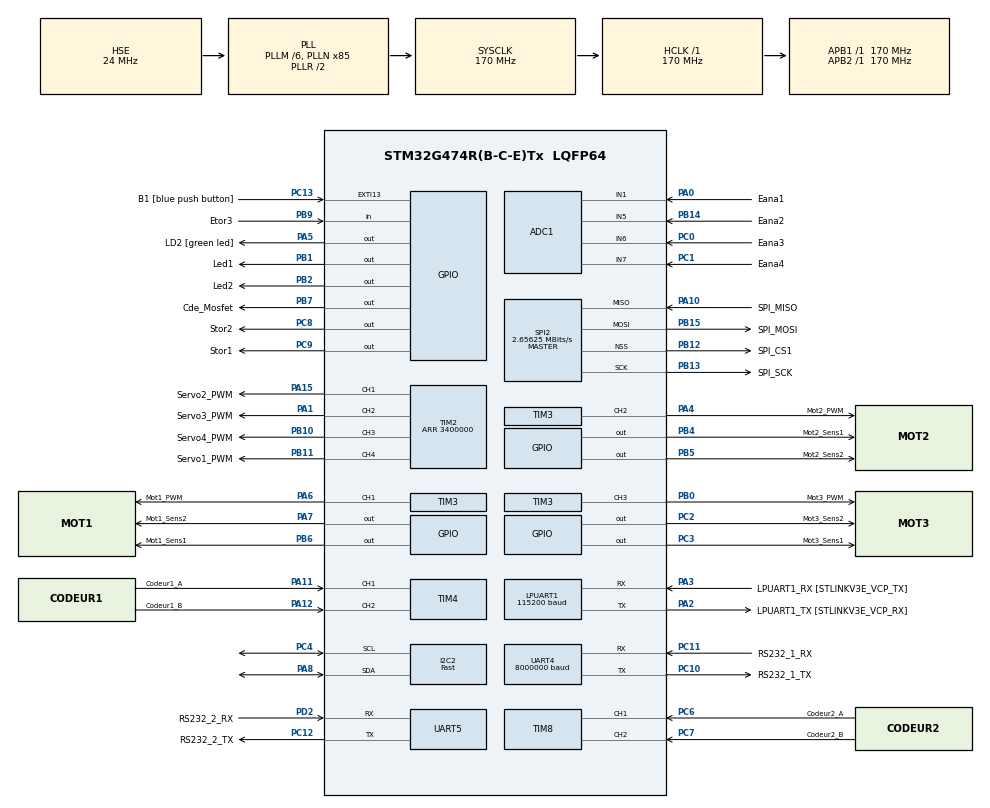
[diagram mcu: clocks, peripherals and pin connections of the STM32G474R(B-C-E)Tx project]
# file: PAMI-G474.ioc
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ADC1.Channel-0\#ChannelRegularConversion=ADC_CHANNEL_1
ADC1.NbrOfConversionFlag=1
ADC1.OffsetNumber-0\#ChannelRegularConversion=ADC_OFFSET_NONE
ADC1.Rank-0\#ChannelRegularConversion=1
ADC1.SamplingTime-0\#ChannelRegularConversion=ADC_SAMPLETIME_2CYCLES_5
ADC1.master=1
Dma.Request0=UART4_TX
Dma.UART4_TX.0.Direction=DMA_MEMORY_TO_PERIPH
Dma.UART4_TX.0.EventEnable=DISABLE
Dma.UART4_TX.0.Instance=DMA1_Channel1
Dma.UART4_TX.0.MemDataAlignment=DMA_MDATAALIGN_BYTE
Dma.UART4_TX.0.MemInc=DMA_MINC_ENABLE
Dma.UART4_TX.0.Mode=DMA_NORMAL
Dma.UART4_TX.0.PeriphDataAlignment=DMA_PDATAALIGN_BYTE
Dma.UART4_TX.0.PeriphInc=DMA_PINC_DISABLE
Dma.UART4_TX.0.Polarity=HAL_DMAMUX_REQ_GEN_RISING
Dma.UART4_TX.0.Priority=DMA_PRIORITY_LOW
Dma.UART4_TX.0.RequestNumber=1
Dma.UART4_TX.0.SignalID=NONE
Dma.UART4_TX.0.SyncEnable=DISABLE
Dma.UART4_TX.0.SyncPolarity=HAL_DMAMUX_SYNC_NO_EVENT
Dma.UART4_TX.0.SyncRequestNumber=1
Dma.UART4_TX.0.SyncSignalID=NONE
I2C2.I2C_Speed_Mode=I2C_Fast
I2C2.Timing=0x40621236
LPUART1.BaudRate=115200
Mcu.Family=STM32G4
Mcu.Name=STM32G474R(B-C-E)Tx
Mcu.Package=LQFP64
NVIC.DMA1_Channel1_IRQn=true\:0\:0\:false\:false\:true\:false\:true\:true
NVIC.EXTI15_10_IRQn=true\:0\:0\:false\:false\:true\:true\:true\:true
NVIC.LPUART1_IRQn=true\:0\:0\:false\:false\:true\:true\:true\:true
NVIC.PriorityGroup=NVIC_PRIORITYGROUP_4
NVIC.UART4_IRQn=true\:0\:0\:false\:false\:true\:true\:true\:true
PA0.GPIO_Label=Eana1
PA0.Mode=IN1-Single-Ended
PA0.Signal=ADC1_IN1
PA1.GPIO_Label=Servo3_PWM
PA1.Signal=S_TIM2_CH2
PA10.GPIO_Label=SPI_MISO
PA10.Mode=Full_Duplex_Master
PA10.Signal=SPI2_MISO
PA11.GPIO_Label=Codeur1_A
PA11.Signal=S_TIM4_CH1
PA12.GPIO_Label=Codeur1_B
PA12.Signal=S_TIM4_CH2
PA13.GPIO_Label=T_SWDIO
PA13.Signal=SYS_JTMS-SWDIO
PA14.GPIO_Label=T_SWCLK
PA14.Signal=SYS_JTCK-SWCLK
PA15.GPIO_Label=Servo2_PWM
PA15.Signal=S_TIM2_CH1
PA2.GPIO_Label=LPUART1_TX [STLINKV3E_VCP_RX]
PA2.Mode=Asynchronous
PA2.Signal=LPUART1_TX
PA3.GPIO_Label=LPUART1_RX [STLINKV3E_VCP_TX]
PA3.Mode=Asynchronous
PA3.Signal=LPUART1_RX
PA4.GPIO_Label=Mot2_PWM
PA4.Signal=S_TIM3_CH2
PA5.GPIO_Label=LD2 [green led]
PA5.Signal=GPIO_Output
PA6.GPIO_Label=Mot1_PWM
PA6.Signal=S_TIM3_CH1
PA7.GPIO_Label=Mot1_Sens2
PA7.Signal=GPIO_Output
PA8.Mode=I2C
PA8.Signal=I2C2_SDA
PB0.GPIO_Label=Mot3_PWM
PB0.Signal=S_TIM3_CH3
PB1.GPIO_Label=Led1
PB1.Signal=GPIO_Output
PB10.GPIO_Label=Servo4_PWM
PB10.Signal=S_TIM2_CH3
PB11.GPIO_Label=Servo1_PWM
PB11.Signal=S_TIM2_CH4
PB12.GPIO_Label=SPI_CS1
PB12.Mode=NSS_Signal_Hard_Output
PB12.Signal=SPI2_NSS
PB13.GPIO_Label=SPI_SCK
PB13.Mode=Full_Duplex_Master
PB13.Signal=SPI2_SCK
PB14.GPIO_Label=Eana2
PB14.Mode=IN5-Single-Ended
PB14.Signal=ADC1_IN5
PB15.GPIO_Label=SPI_MOSI
PB15.Mode=Full_Duplex_Master
PB15.Signal=SPI2_MOSI
PB2.GPIO_Label=Led2
PB2.Signal=GPIO_Output
PB3.GPIO_Label=T_SWO
PB3.Signal=SYS_JTDO-SWO
PB4.GPIO_Label=Mot2_Sens1
PB4.Signal=GPIO_Output
PB5.GPIO_Label=Mot2_Sens2
PB5.Signal=GPIO_Output
PB6.GPIO_Label=Mot1_Sens1
PB6.Signal=GPIO_Output
PB7.GPIO_Label=Cde_Mosfet
PB7.Signal=GPIO_Output
PB9.GPIO_Label=Etor3
PB9.GPIO_PuPd=GPIO_PULLUP
PB9.Signal=GPIO_Input
PC0.GPIO_Label=Eana3
PC0.Mode=IN6-Single-Ended
PC0.Signal=ADC1_IN6
PC1.GPIO_Label=Eana4
PC1.Mode=IN7-Single-Ended
PC1.Signal=ADC1_IN7
PC10.GPIO_Label=RS232_1_TX
PC10.Mode=Asynchronous
PC10.Signal=UART4_TX
PC11.GPIO_Label=RS232_1_RX
PC11.Mode=Asynchronous
PC11.Signal=UART4_RX
PC12.GPIO_Label=RS232_2_TX
PC12.Mode=Asynchronous
PC12.Signal=UART5_TX
PC13.GPIO_Label=B1 [blue push button]
PC13.Signal=GPXTI13
PC14-OSC32_IN.GPIO_Label=RCC_OSC32_IN
PC14-OSC32_IN.Signal=RCC_OSC32_IN
PC15-OSC32_OUT.GPIO_Label=RCC_OSC32_OUT
PC15-OSC32_OUT.Signal=RCC_OSC32_OUT
PC2.GPIO_Label=Mot3_Sens2
PC2.Signal=GPIO_Output
PC3.GPIO_Label=Mot3_Sens1
PC3.Signal=GPIO_Output
PC4.Mode=I2C
PC4.Signal=I2C2_SCL
PC6.GPIO_Label=Codeur2_A
PC6.Signal=S_TIM8_CH1
PC7.GPIO_Label=Codeur2_B
PC7.Signal=S_TIM8_CH2
PC8.GPIO_Label=Stor2
PC8.Signal=GPIO_Output
PC9.GPIO_Label=Stor1
PC9.Signal=GPIO_Output
PD2.GPIO_Label=RS232_2_RX
PD2.Mode=Asynchronous
PD2.Signal=UART5_RX
PF0-OSC_IN.GPIO_Label=RCC_OSC_IN
PF0-OSC_IN.Mode=HSE-External-Oscillator
PF0-OSC_IN.Signal=RCC_OSC_IN
PF1-OSC_OUT.GPIO_Label=RCC_OSC_OUT
PF1-OSC_OUT.Mode=HSE-External-Oscillator
PF1-OSC_OUT.Signal=RCC_OSC_OUT
ProjectManager.HeapSize=0x200
ProjectManager.StackSize=0x400
ProjectManager.TargetToolchain=STM32CubeIDE
RCC.ADC12Freq_Value=170000000
RCC.ADC345Freq_Value=170000000
RCC.AHBFreq_Value=170000000
RCC.APB1Freq_Value=170000000
RCC.APB1TimFreq_Value=170000000
RCC.APB2Freq_Value=170000000
RCC.APB2TimFreq_Value=170000000
RCC.CortexFreq_Value=170000000
RCC.EXTERNAL_CLOCK_VALUE=12288000
RCC.HCLKFreq_Value=170000000
RCC.HSE_VALUE=24000000
RCC.HSI48_VALUE=48000000
RCC.HSI_VALUE=16000000
RCC.LSE_VALUE=32768
RCC.PLLM=RCC_PLLM_DIV6
RCC.PLLN=85
RCC.PLLSourceVirtual=RCC_PLLSOURCE_HSE
RCC.RTCClockSelection=RCC_RTCCLKSOURCE_LSE
RCC.SYSCLKFreq_VALUE=170000000
RCC.SYSCLKSource=RCC_SYSCLKSOURCE_PLLCLK
RCC.USBFreq_Value=170000000
RCC.VCOOutputFreq_Value=340000000
SH.S_TIM2_CH1.0=TIM2_CH1,PWM Generation1 CH1
SH.S_TIM2_CH2.0=TIM2_CH2,PWM Generation2 CH2
SH.S_TIM2_CH3.0=TIM2_CH3,PWM Generation3 CH3
SH.S_TIM2_CH4.0=TIM2_CH4,PWM Generation4 CH4
SH.S_TIM3_CH1.0=TIM3_CH1,PWM Generation1 CH1
SH.S_TIM3_CH2.0=TIM3_CH2,PWM Generation2 CH2
SH.S_TIM3_CH3.0=TIM3_CH3,PWM Generation3 CH3
SH.S_TIM4_CH1.0=TIM4_CH1,Encoder_Interface
SH.S_TIM4_CH2.0=TIM4_CH2,Encoder_Interface
SH.S_TIM8_CH1.0=TIM8_CH1,Encoder_Interface
SH.S_TIM8_CH2.0=TIM8_CH2,Encoder_Interface
SPI2.BaudRatePrescaler=SPI_BAUDRATEPRESCALER_64
SPI2.CalculateBaudRate=2.65625 MBits/s
SPI2.DataSize=SPI_DATASIZE_8BIT
SPI2.Direction=SPI_DIRECTION_2LINES
SPI2.Mode=SPI_MODE_MASTER
SPI2.VirtualNSS=VM_NSSHARD
SPI2.VirtualType=VM_MASTER
TIM2.Channel-PWM\ Generation1\ CH1=TIM_CHANNEL_1
TIM2.Channel-PWM\ Generation2\ CH2=TIM_CHANNEL_2
TIM2.Channel-PWM\ Generation3\ CH3=TIM_CHANNEL_3
TIM2.Channel-PWM\ Generation4\ CH4=TIM_CHANNEL_4
TIM2.PeriodNoDither=3400000
TIM3.Channel-PWM\ Generation1\ CH1=TIM_CHANNEL_1
TIM3.Channel-PWM\ Generation2\ CH2=TIM_CHANNEL_2
TIM3.Channel-PWM\ Generation3\ CH3=TIM_CHANNEL_3
TIM3.PeriodNoDither=8500
TIM3.PulseNoDither_3=800
TIM4.EncoderMode=TIM_ENCODERMODE_TI12
TIM8.EncoderMode=TIM_ENCODERMODE_TI12
UART4.BaudRate=8000000
UART4.Mode=MODE_TX
UART4.TxPinLevelInvertParam=UART_ADVFEATURE_TXINV_ENABLE
VP_SYS_VS_DBSignals.Mode=DisableDeadBatterySignals
board=NUCLEO-G474RE

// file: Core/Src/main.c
/* USER CODE BEGIN Header */
/**
  ******************************************************************************
  * @file           : main.c
  * @brief          : Main program body
  ******************************************************************************
  * @attention
  *
  * Copyright (c) 2026 STMicroelectronics.
  * All rights reserved.
  *
  * This software is licensed under terms that can be found in the LICENSE file
  * in the root directory of this software component.
  * If no LICENSE file comes with this software, it is provided AS-IS.
  *
  ******************************************************************************
  */
/* USER CODE END Header */
#include "main.h"

ADC_HandleTypeDef hadc1;

I2C_HandleTypeDef hi2c2;

UART_HandleTypeDef hlpuart1;
UART_HandleTypeDef huart4;
UART_HandleTypeDef huart5;
DMA_HandleTypeDef hdma_uart4_tx;

SPI_HandleTypeDef hspi2;

TIM_HandleTypeDef htim2;
TIM_HandleTypeDef htim3;
TIM_HandleTypeDef htim4;
TIM_HandleTypeDef htim8;

void SystemClock_Config(void);
static void MX_GPIO_Init(void);
static void MX_DMA_Init(void);
static void MX_UART4_Init(void);
static void MX_UART5_Init(void);
static void MX_I2C2_Init(void);
static void MX_SPI2_Init(void);
static void MX_TIM2_Init(void);
static void MX_TIM3_Init(void);
static void MX_TIM4_Init(void);
static void MX_TIM8_Init(void);
static void MX_ADC1_Init(void);
static void MX_LPUART1_UART_Init(void);

int main(void)
{

  /* MCU Configuration--------------------------------------------------------*/

  /* Reset of all peripherals, Initializes the Flash interface and the Systick. */
  HAL_Init();

  /* Configure the system clock */
  SystemClock_Config();

  /* Initialize all configured peripherals */
  MX_GPIO_Init();
  MX_DMA_Init();
  MX_UART4_Init();
  MX_UART5_Init();
  MX_I2C2_Init();
  MX_SPI2_Init();
  MX_TIM2_Init();
  MX_TIM3_Init();
  MX_TIM4_Init();
  MX_TIM8_Init();
  MX_ADC1_Init();
  MX_LPUART1_UART_Init();
  /* USER CODE BEGIN 2 */
  main_app();
  /* USER CODE END 2 */

  /* Infinite loop */
  while (1)
  {

  }
}

void SystemClock_Config(void)
{
  RCC_OscInitTypeDef RCC_OscInitStruct = {0};
  RCC_ClkInitTypeDef RCC_ClkInitStruct = {0};

  /** Configure the main internal regulator output voltage
  */
  HAL_PWREx_ControlVoltageScaling(PWR_REGULATOR_VOLTAGE_SCALE1_BOOST);

  /** Initializes the RCC Oscillators according to the specified parameters
  * in the RCC_OscInitTypeDef structure.
  */
  RCC_OscInitStruct.OscillatorType = RCC_OSCILLATORTYPE_HSE;
  RCC_OscInitStruct.HSEState = RCC_HSE_ON;
  RCC_OscInitStruct.PLL.PLLState = RCC_PLL_ON;
  RCC_OscInitStruct.PLL.PLLSource = RCC_PLLSOURCE_HSE;
  RCC_OscInitStruct.PLL.PLLM = RCC_PLLM_DIV6;
  RCC_OscInitStruct.PLL.PLLN = 85;
  RCC_OscInitStruct.PLL.PLLP = RCC_PLLP_DIV2;
  RCC_OscInitStruct.PLL.PLLQ = RCC_PLLQ_DIV2;
  RCC_OscInitStruct.PLL.PLLR = RCC_PLLR_DIV2;
  if (HAL_RCC_OscConfig(&RCC_OscInitStruct) != HAL_OK)
  {
    Error_Handler();
  }

  /** Initializes the CPU, AHB and APB buses clocks
  */
  RCC_ClkInitStruct.ClockType = RCC_CLOCKTYPE_HCLK|RCC_CLOCKTYPE_SYSCLK
                              |RCC_CLOCKTYPE_PCLK1|RCC_CLOCKTYPE_PCLK2;
  RCC_ClkInitStruct.SYSCLKSource = RCC_SYSCLKSOURCE_PLLCLK;
  RCC_ClkInitStruct.AHBCLKDivider = RCC_SYSCLK_DIV1;
  RCC_ClkInitStruct.APB1CLKDivider = RCC_HCLK_DIV1;
  RCC_ClkInitStruct.APB2CLKDivider = RCC_HCLK_DIV1;

  if (HAL_RCC_ClockConfig(&RCC_ClkInitStruct, FLASH_LATENCY_4) != HAL_OK)
  {
    Error_Handler();
  }
}

static void MX_ADC1_Init(void)
{

  ADC_MultiModeTypeDef multimode = {0};
  ADC_ChannelConfTypeDef sConfig = {0};

  /** Common config
  */
  hadc1.Instance = ADC1;
  hadc1.Init.ClockPrescaler = ADC_CLOCK_SYNC_PCLK_DIV4;
  hadc1.Init.Resolution = ADC_RESOLUTION_12B;
  hadc1.Init.DataAlign = ADC_DATAALIGN_RIGHT;
  hadc1.Init.GainCompensation = 0;
  hadc1.Init.ScanConvMode = ADC_SCAN_DISABLE;
  hadc1.Init.EOCSelection = ADC_EOC_SINGLE_CONV;
  hadc1.Init.LowPowerAutoWait = DISABLE;
  hadc1.Init.ContinuousConvMode = DISABLE;
  hadc1.Init.NbrOfConversion = 1;
  hadc1.Init.DiscontinuousConvMode = DISABLE;
  hadc1.Init.ExternalTrigConv = ADC_SOFTWARE_START;
  hadc1.Init.ExternalTrigConvEdge = ADC_EXTERNALTRIGCONVEDGE_NONE;
  hadc1.Init.DMAContinuousRequests = DISABLE;
  hadc1.Init.Overrun = ADC_OVR_DATA_PRESERVED;
  hadc1.Init.OversamplingMode = DISABLE;
  if (HAL_ADC_Init(&hadc1) != HAL_OK)
  {
    Error_Handler();
  }

  /** Configure the ADC multi-mode
  */
  multimode.Mode = ADC_MODE_INDEPENDENT;
  if (HAL_ADCEx_MultiModeConfigChannel(&hadc1, &multimode) != HAL_OK)
  {
    Error_Handler();
  }

  /** Configure Regular Channel
  */
  sConfig.Channel = ADC_CHANNEL_1;
  sConfig.Rank = ADC_REGULAR_RANK_1;
  sConfig.SamplingTime = ADC_SAMPLETIME_2CYCLES_5;
  sConfig.SingleDiff = ADC_SINGLE_ENDED;
  sConfig.OffsetNumber = ADC_OFFSET_NONE;
  sConfig.Offset = 0;
  if (HAL_ADC_ConfigChannel(&hadc1, &sConfig) != HAL_OK)
  {
    Error_Handler();
  }

}

static void MX_I2C2_Init(void)
{

  hi2c2.Instance = I2C2;
  hi2c2.Init.Timing = 0x40621236;
  hi2c2.Init.OwnAddress1 = 0;
  hi2c2.Init.AddressingMode = I2C_ADDRESSINGMODE_7BIT;
  hi2c2.Init.DualAddressMode = I2C_DUALADDRESS_DISABLE;
  hi2c2.Init.OwnAddress2 = 0;
  hi2c2.Init.OwnAddress2Masks = I2C_OA2_NOMASK;
  hi2c2.Init.GeneralCallMode = I2C_GENERALCALL_DISABLE;
  hi2c2.Init.NoStretchMode = I2C_NOSTRETCH_DISABLE;
  if (HAL_I2C_Init(&hi2c2) != HAL_OK)
  {
    Error_Handler();
  }

  /** Configure Analogue filter
  */
  if (HAL_I2CEx_ConfigAnalogFilter(&hi2c2, I2C_ANALOGFILTER_ENABLE) != HAL_OK)
  {
    Error_Handler();
  }

  /** Configure Digital filter
  */
  if (HAL_I2CEx_ConfigDigitalFilter(&hi2c2, 0) != HAL_OK)
  {
    Error_Handler();
  }

}

static void MX_LPUART1_UART_Init(void)
{

  hlpuart1.Instance = LPUART1;
  hlpuart1.Init.BaudRate = 115200;
  hlpuart1.Init.WordLength = UART_WORDLENGTH_8B;
  hlpuart1.Init.StopBits = UART_STOPBITS_1;
  hlpuart1.Init.Parity = UART_PARITY_NONE;
  hlpuart1.Init.Mode = UART_MODE_TX_RX;
  hlpuart1.Init.HwFlowCtl = UART_HWCONTROL_NONE;
  hlpuart1.Init.OneBitSampling = UART_ONE_BIT_SAMPLE_DISABLE;
  hlpuart1.Init.ClockPrescaler = UART_PRESCALER_DIV1;
  hlpuart1.AdvancedInit.AdvFeatureInit = UART_ADVFEATURE_NO_INIT;
  if (HAL_UART_Init(&hlpuart1) != HAL_OK)
  {
    Error_Handler();
  }
  if (HAL_UARTEx_SetTxFifoThreshold(&hlpuart1, UART_TXFIFO_THRESHOLD_1_8) != HAL_OK)
  {
    Error_Handler();
  }
  if (HAL_UARTEx_SetRxFifoThreshold(&hlpuart1, UART_RXFIFO_THRESHOLD_1_8) != HAL_OK)
  {
    Error_Handler();
  }
  if (HAL_UARTEx_DisableFifoMode(&hlpuart1) != HAL_OK)
  {
    Error_Handler();
  }

}

static void MX_UART4_Init(void)
{

  huart4.Instance = UART4;
  huart4.Init.BaudRate = 8000000;
  huart4.Init.WordLength = UART_WORDLENGTH_8B;
  huart4.Init.StopBits = UART_STOPBITS_1;
  huart4.Init.Parity = UART_PARITY_NONE;
  huart4.Init.Mode = UART_MODE_TX;
  huart4.Init.HwFlowCtl = UART_HWCONTROL_NONE;
  huart4.Init.OverSampling = UART_OVERSAMPLING_16;
  huart4.Init.OneBitSampling = UART_ONE_BIT_SAMPLE_DISABLE;
  huart4.Init.ClockPrescaler = UART_PRESCALER_DIV1;
  huart4.AdvancedInit.AdvFeatureInit = UART_ADVFEATURE_TXINVERT_INIT;
  huart4.AdvancedInit.TxPinLevelInvert = UART_ADVFEATURE_TXINV_ENABLE;
  if (HAL_UART_Init(&huart4) != HAL_OK)
  {
    Error_Handler();
  }
  if (HAL_UARTEx_SetTxFifoThreshold(&huart4, UART_TXFIFO_THRESHOLD_1_8) != HAL_OK)
  {
    Error_Handler();
  }
  if (HAL_UARTEx_SetRxFifoThreshold(&huart4, UART_RXFIFO_THRESHOLD_1_8) != HAL_OK)
  {
    Error_Handler();
  }
  if (HAL_UARTEx_DisableFifoMode(&huart4) != HAL_OK)
  {
    Error_Handler();
  }

}

static void MX_UART5_Init(void)
{

  huart5.Instance = UART5;
  huart5.Init.BaudRate = 115200;
  huart5.Init.WordLength = UART_WORDLENGTH_8B;
  huart5.Init.StopBits = UART_STOPBITS_1;
  huart5.Init.Parity = UART_PARITY_NONE;
  huart5.Init.Mode = UART_MODE_TX_RX;
  huart5.Init.HwFlowCtl = UART_HWCONTROL_NONE;
  huart5.Init.OverSampling = UART_OVERSAMPLING_16;
  huart5.Init.OneBitSampling = UART_ONE_BIT_SAMPLE_DISABLE;
  huart5.Init.ClockPrescaler = UART_PRESCALER_DIV1;
  huart5.AdvancedInit.AdvFeatureInit = UART_ADVFEATURE_NO_INIT;
  if (HAL_UART_Init(&huart5) != HAL_OK)
  {
    Error_Handler();
  }
  if (HAL_UARTEx_SetTxFifoThreshold(&huart5, UART_TXFIFO_THRESHOLD_1_8) != HAL_OK)
  {
    Error_Handler();
  }
  if (HAL_UARTEx_SetRxFifoThreshold(&huart5, UART_RXFIFO_THRESHOLD_1_8) != HAL_OK)
  {
    Error_Handler();
  }
  if (HAL_UARTEx_DisableFifoMode(&huart5) != HAL_OK)
  {
    Error_Handler();
  }

}

static void MX_SPI2_Init(void)
{

  /* SPI2 parameter configuration*/
  hspi2.Instance = SPI2;
  hspi2.Init.Mode = SPI_MODE_MASTER;
  hspi2.Init.Direction = SPI_DIRECTION_2LINES;
  hspi2.Init.DataSize = SPI_DATASIZE_8BIT;
  hspi2.Init.CLKPolarity = SPI_POLARITY_LOW;
  hspi2.Init.CLKPhase = SPI_PHASE_1EDGE;
  hspi2.Init.NSS = SPI_NSS_HARD_OUTPUT;
  hspi2.Init.BaudRatePrescaler = SPI_BAUDRATEPRESCALER_64;
  hspi2.Init.FirstBit = SPI_FIRSTBIT_MSB;
  hspi2.Init.TIMode = SPI_TIMODE_DISABLE;
  hspi2.Init.CRCCalculation = SPI_CRCCALCULATION_DISABLE;
  hspi2.Init.CRCPolynomial = 7;
  hspi2.Init.CRCLength = SPI_CRC_LENGTH_DATASIZE;
  hspi2.Init.NSSPMode = SPI_NSS_PULSE_ENABLE;
  if (HAL_SPI_Init(&hspi2) != HAL_OK)
  {
    Error_Handler();
  }

}

static void MX_TIM2_Init(void)
{

  TIM_MasterConfigTypeDef sMasterConfig = {0};
  TIM_OC_InitTypeDef sConfigOC = {0};

  htim2.Instance = TIM2;
  htim2.Init.Prescaler = 0;
  htim2.Init.CounterMode = TIM_COUNTERMODE_UP;
  htim2.Init.Period = 3400000;
  htim2.Init.ClockDivision = TIM_CLOCKDIVISION_DIV1;
  htim2.Init.AutoReloadPreload = TIM_AUTORELOAD_PRELOAD_DISABLE;
  if (HAL_TIM_PWM_Init(&htim2) != HAL_OK)
  {
    Error_Handler();
  }
  sMasterConfig.MasterOutputTrigger = TIM_TRGO_RESET;
  sMasterConfig.MasterSlaveMode = TIM_MASTERSLAVEMODE_DISABLE;
  if (HAL_TIMEx_MasterConfigSynchronization(&htim2, &sMasterConfig) != HAL_OK)
  {
    Error_Handler();
  }
  sConfigOC.OCMode = TIM_OCMODE_PWM1;
  sConfigOC.Pulse = 0;
  sConfigOC.OCPolarity = TIM_OCPOLARITY_HIGH;
  sConfigOC.OCFastMode = TIM_OCFAST_DISABLE;
  if (HAL_TIM_PWM_ConfigChannel(&htim2, &sConfigOC, TIM_CHANNEL_1) != HAL_OK)
  {
    Error_Handler();
  }
  if (HAL_TIM_PWM_ConfigChannel(&htim2, &sConfigOC, TIM_CHANNEL_2) != HAL_OK)
  {
    Error_Handler();
  }
  if (HAL_TIM_PWM_ConfigChannel(&htim2, &sConfigOC, TIM_CHANNEL_3) != HAL_OK)
  {
    Error_Handler();
  }
  if (HAL_TIM_PWM_ConfigChannel(&htim2, &sConfigOC, TIM_CHANNEL_4) != HAL_OK)
  {
    Error_Handler();
  }
  HAL_TIM_MspPostInit(&htim2);

}

static void MX_TIM3_Init(void)
{

  TIM_MasterConfigTypeDef sMasterConfig = {0};
  TIM_OC_InitTypeDef sConfigOC = {0};

  htim3.Instance = TIM3;
  htim3.Init.Prescaler = 0;
  htim3.Init.CounterMode = TIM_COUNTERMODE_UP;
  htim3.Init.Period = 8500;
  htim3.Init.ClockDivision = TIM_CLOCKDIVISION_DIV1;
  htim3.Init.AutoReloadPreload = TIM_AUTORELOAD_PRELOAD_DISABLE;
  if (HAL_TIM_PWM_Init(&htim3) != HAL_OK)
  {
    Error_Handler();
  }
  sMasterConfig.MasterOutputTrigger = TIM_TRGO_RESET;
  sMasterConfig.MasterSlaveMode = TIM_MASTERSLAVEMODE_DISABLE;
  if (HAL_TIMEx_MasterConfigSynchronization(&htim3, &sMasterConfig) != HAL_OK)
  {
    Error_Handler();
  }
  sConfigOC.OCMode = TIM_OCMODE_PWM1;
  sConfigOC.Pulse = 0;
  sConfigOC.OCPolarity = TIM_OCPOLARITY_HIGH;
  sConfigOC.OCFastMode = TIM_OCFAST_DISABLE;
  if (HAL_TIM_PWM_ConfigChannel(&htim3, &sConfigOC, TIM_CHANNEL_1) != HAL_OK)
  {
    Error_Handler();
  }
  if (HAL_TIM_PWM_ConfigChannel(&htim3, &sConfigOC, TIM_CHANNEL_2) != HAL_OK)
  {
    Error_Handler();
  }
  sConfigOC.Pulse = 800;
  if (HAL_TIM_PWM_ConfigChannel(&htim3, &sConfigOC, TIM_CHANNEL_3) != HAL_OK)
  {
    Error_Handler();
  }
  HAL_TIM_MspPostInit(&htim3);

}

static void MX_TIM4_Init(void)
{

  TIM_Encoder_InitTypeDef sConfig = {0};
  TIM_MasterConfigTypeDef sMasterConfig = {0};

  htim4.Instance = TIM4;
  htim4.Init.Prescaler = 0;
  htim4.Init.CounterMode = TIM_COUNTERMODE_UP;
  htim4.Init.Period = 65535;
  htim4.Init.ClockDivision = TIM_CLOCKDIVISION_DIV1;
  htim4.Init.AutoReloadPreload = TIM_AUTORELOAD_PRELOAD_DISABLE;
  sConfig.EncoderMode = TIM_ENCODERMODE_TI12;
  sConfig.IC1Polarity = TIM_ICPOLARITY_RISING;
  sConfig.IC1Selection = TIM_ICSELECTION_DIRECTTI;
  sConfig.IC1Prescaler = TIM_ICPSC_DIV1;
  sConfig.IC1Filter = 0;
  sConfig.IC2Polarity = TIM_ICPOLARITY_RISING;
  sConfig.IC2Selection = TIM_ICSELECTION_DIRECTTI;
  sConfig.IC2Prescaler = TIM_ICPSC_DIV1;
  sConfig.IC2Filter = 0;
  if (HAL_TIM_Encoder_Init(&htim4, &sConfig) != HAL_OK)
  {
    Error_Handler();
  }
  sMasterConfig.MasterOutputTrigger = TIM_TRGO_RESET;
  sMasterConfig.MasterSlaveMode = TIM_MASTERSLAVEMODE_DISABLE;
  if (HAL_TIMEx_MasterConfigSynchronization(&htim4, &sMasterConfig) != HAL_OK)
  {
    Error_Handler();
  }

}

static void MX_TIM8_Init(void)
{

  TIM_Encoder_InitTypeDef sConfig = {0};
  TIM_MasterConfigTypeDef sMasterConfig = {0};

  htim8.Instance = TIM8;
  htim8.Init.Prescaler = 0;
  htim8.Init.CounterMode = TIM_COUNTERMODE_UP;
  htim8.Init.Period = 65535;
  htim8.Init.ClockDivision = TIM_CLOCKDIVISION_DIV1;
  htim8.Init.RepetitionCounter = 0;
  htim8.Init.AutoReloadPreload = TIM_AUTORELOAD_PRELOAD_DISABLE;
  sConfig.EncoderMode = TIM_ENCODERMODE_TI12;
  sConfig.IC1Polarity = TIM_ICPOLARITY_RISING;
  sConfig.IC1Selection = TIM_ICSELECTION_DIRECTTI;
  sConfig.IC1Prescaler = TIM_ICPSC_DIV1;
  sConfig.IC1Filter = 0;
  sConfig.IC2Polarity = TIM_ICPOLARITY_RISING;
  sConfig.IC2Selection = TIM_ICSELECTION_DIRECTTI;
  sConfig.IC2Prescaler = TIM_ICPSC_DIV1;
  sConfig.IC2Filter = 0;
  if (HAL_TIM_Encoder_Init(&htim8, &sConfig) != HAL_OK)
  {
    Error_Handler();
  }
  sMasterConfig.MasterOutputTrigger = TIM_TRGO_RESET;
  sMasterConfig.MasterOutputTrigger2 = TIM_TRGO2_RESET;
  sMasterConfig.MasterSlaveMode = TIM_MASTERSLAVEMODE_DISABLE;
  if (HAL_TIMEx_MasterConfigSynchronization(&htim8, &sMasterConfig) != HAL_OK)
  {
    Error_Handler();
  }

}

static void MX_DMA_Init(void)
{

  /* DMA controller clock enable */
  __HAL_RCC_DMAMUX1_CLK_ENABLE();
  __HAL_RCC_DMA1_CLK_ENABLE();

  /* DMA interrupt init */
  /* DMA1_Channel1_IRQn interrupt configuration */
  HAL_NVIC_SetPriority(DMA1_Channel1_IRQn, 0, 0);
  HAL_NVIC_EnableIRQ(DMA1_Channel1_IRQn);

}

static void MX_GPIO_Init(void)
{
  GPIO_InitTypeDef GPIO_InitStruct = {0};

  /* GPIO Ports Clock Enable */
  __HAL_RCC_GPIOC_CLK_ENABLE();
  __HAL_RCC_GPIOF_CLK_ENABLE();
  __HAL_RCC_GPIOA_CLK_ENABLE();
  __HAL_RCC_GPIOB_CLK_ENABLE();
  __HAL_RCC_GPIOD_CLK_ENABLE();

  /*Configure GPIO pin Output Level */
  HAL_GPIO_WritePin(GPIOC, Mot3_Sens2_Pin|Mot3_Sens1_Pin|Stor2_Pin|Stor1_Pin, GPIO_PIN_RESET);

  /*Configure GPIO pin Output Level */
  HAL_GPIO_WritePin(GPIOA, LD2_Pin|Mot1_Sens2_Pin, GPIO_PIN_RESET);

  /*Configure GPIO pin Output Level */
  HAL_GPIO_WritePin(GPIOB, Led1_Pin|Led2_Pin|Mot2_Sens1_Pin|Mot2_Sens2_Pin
                          |Mot1_Sens1_Pin|Cde_Mosfet_Pin, GPIO_PIN_RESET);

  /*Configure GPIO pin : B1_Pin */
  GPIO_InitStruct.Pin = B1_Pin;
  GPIO_InitStruct.Mode = GPIO_MODE_IT_RISING;
  GPIO_InitStruct.Pull = GPIO_NOPULL;
  HAL_GPIO_Init(B1_GPIO_Port, &GPIO_InitStruct);

  /*Configure GPIO pins : Mot3_Sens2_Pin Mot3_Sens1_Pin Stor2_Pin Stor1_Pin */
  GPIO_InitStruct.Pin = Mot3_Sens2_Pin|Mot3_Sens1_Pin|Stor2_Pin|Stor1_Pin;
  GPIO_InitStruct.Mode = GPIO_MODE_OUTPUT_PP;
  GPIO_InitStruct.Pull = GPIO_NOPULL;
  GPIO_InitStruct.Speed = GPIO_SPEED_FREQ_LOW;
  HAL_GPIO_Init(GPIOC, &GPIO_InitStruct);

  /*Configure GPIO pins : LD2_Pin Mot1_Sens2_Pin */
  GPIO_InitStruct.Pin = LD2_Pin|Mot1_Sens2_Pin;
  GPIO_InitStruct.Mode = GPIO_MODE_OUTPUT_PP;
  GPIO_InitStruct.Pull = GPIO_NOPULL;
  GPIO_InitStruct.Speed = GPIO_SPEED_FREQ_LOW;
  HAL_GPIO_Init(GPIOA, &GPIO_InitStruct);

  /*Configure GPIO pins : Led1_Pin Led2_Pin Mot2_Sens1_Pin Mot2_Sens2_Pin
                           Mot1_Sens1_Pin Cde_Mosfet_Pin */
  GPIO_InitStruct.Pin = Led1_Pin|Led2_Pin|Mot2_Sens1_Pin|Mot2_Sens2_Pin
                          |Mot1_Sens1_Pin|Cde_Mosfet_Pin;
  GPIO_InitStruct.Mode = GPIO_MODE_OUTPUT_PP;
  GPIO_InitStruct.Pull = GPIO_NOPULL;
  GPIO_InitStruct.Speed = GPIO_SPEED_FREQ_LOW;
  HAL_GPIO_Init(GPIOB, &GPIO_InitStruct);

  /*Configure GPIO pin : Etor3_Pin */
  GPIO_InitStruct.Pin = Etor3_Pin;
  GPIO_InitStruct.Mode = GPIO_MODE_INPUT;
  GPIO_InitStruct.Pull = GPIO_PULLUP;
  HAL_GPIO_Init(Etor3_GPIO_Port, &GPIO_InitStruct);

  /* EXTI interrupt init*/
  HAL_NVIC_SetPriority(EXTI15_10_IRQn, 0, 0);
  HAL_NVIC_EnableIRQ(EXTI15_10_IRQn);

}

void Error_Handler(void)
{
  __disable_irq();
  while (1)
  {
  }
}
